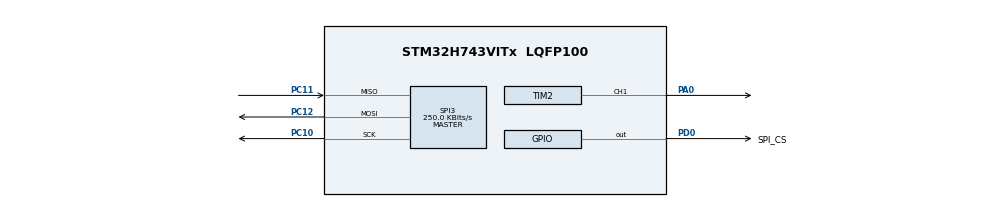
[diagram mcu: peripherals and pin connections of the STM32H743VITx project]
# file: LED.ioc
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Dma.Request0=SPI3_RX
Dma.SPI3_RX.0.Direction=DMA_PERIPH_TO_MEMORY
Dma.SPI3_RX.0.EventEnable=DISABLE
Dma.SPI3_RX.0.FIFOMode=DMA_FIFOMODE_DISABLE
Dma.SPI3_RX.0.Instance=DMA1_Stream3
Dma.SPI3_RX.0.MemDataAlignment=DMA_MDATAALIGN_BYTE
Dma.SPI3_RX.0.MemInc=DMA_MINC_ENABLE
Dma.SPI3_RX.0.Mode=DMA_CIRCULAR
Dma.SPI3_RX.0.PeriphDataAlignment=DMA_PDATAALIGN_BYTE
Dma.SPI3_RX.0.PeriphInc=DMA_PINC_DISABLE
Dma.SPI3_RX.0.Polarity=HAL_DMAMUX_REQ_GEN_RISING
Dma.SPI3_RX.0.Priority=DMA_PRIORITY_LOW
Dma.SPI3_RX.0.RequestNumber=1
Dma.SPI3_RX.0.SignalID=NONE
Dma.SPI3_RX.0.SyncEnable=DISABLE
Dma.SPI3_RX.0.SyncPolarity=HAL_DMAMUX_SYNC_NO_EVENT
Dma.SPI3_RX.0.SyncRequestNumber=1
Dma.SPI3_RX.0.SyncSignalID=NONE
Mcu.Family=STM32H7
Mcu.Name=STM32H743VITx
Mcu.Package=LQFP100
NVIC.DMA1_Stream3_IRQn=true\:0\:0\:false\:false\:true\:false\:true
NVIC.PriorityGroup=NVIC_PRIORITYGROUP_4
NVIC.SPI3_IRQn=true\:0\:0\:false\:false\:true\:false\:true
PA0.Signal=S_TIM2_CH1
PA13\ (JTMS/SWDIO).Mode=JTAG_4_pins
PA13\ (JTMS/SWDIO).Signal=DEBUG_JTMS-SWDIO
PA14\ (JTCK/SWCLK).Mode=JTAG_4_pins
PA14\ (JTCK/SWCLK).Signal=DEBUG_JTCK-SWCLK
PA15\ (JTDI).Mode=JTAG_4_pins
PA15\ (JTDI).Signal=DEBUG_JTDI
PB3\ (JTDO/TRACESWO).Mode=JTAG_4_pins
PB3\ (JTDO/TRACESWO).Signal=DEBUG_JTDO-SWO
PC10.Mode=Full_Duplex_Master
PC10.Signal=SPI3_SCK
PC11.Mode=Full_Duplex_Master
PC11.Signal=SPI3_MISO
PC12.Mode=Full_Duplex_Master
PC12.Signal=SPI3_MOSI
PD0.GPIO_Label=SPI_CS
PD0.Signal=GPIO_Output
PH0-OSC_IN\ (PH0).Mode=HSE-External-Oscillator
PH0-OSC_IN\ (PH0).Signal=RCC_OSC_IN
PH1-OSC_OUT\ (PH1).Mode=HSE-External-Oscillator
PH1-OSC_OUT\ (PH1).Signal=RCC_OSC_OUT
ProjectManager.HeapSize=0x200
ProjectManager.StackSize=0x400
ProjectManager.TargetToolchain=MDK-ARM V5
RCC.ADCFreq_Value=16125000
RCC.APB1Freq_Value=100000000
RCC.APB2Freq_Value=100000000
RCC.APB3Freq_Value=100000000
RCC.APB4Freq_Value=100000000
RCC.CortexFreq_Value=400000000
RCC.D1PPRE=RCC_APB3_DIV2
RCC.D2PPRE1=RCC_APB1_DIV2
RCC.D2PPRE2=RCC_APB2_DIV2
RCC.D3PPRE=RCC_APB4_DIV2
RCC.DIVM1=1
RCC.DIVN1=100
RCC.EnbaleCSS=true
RCC.HCLKFreq_Value=200000000
RCC.HPRE=RCC_HCLK_DIV2
RCC.HSE_VALUE=8000000
RCC.PLL2FRACN=0
RCC.PLL2_VCI_Range-AdvancedSettings=RCC_PLL2VCIRANGE_0
RCC.PLL3FRACN=0
RCC.PLLFRACN=0
RCC.PLLSourceVirtual=RCC_PLLSOURCE_HSE
RCC.SPI123CLockSelection=RCC_SPI123CLKSOURCE_CLKP
RCC.SYSCLKFreq_VALUE=400000000
RCC.SYSCLKSource=RCC_SYSCLKSOURCE_PLLCLK
RCC.USBFreq_Value=400000000
SH.S_TIM2_CH1.0=TIM2_CH1,PWM Generation1 CH1
SPI3.BaudRatePrescaler=SPI_BAUDRATEPRESCALER_256
SPI3.CLKPhase=SPI_PHASE_2EDGE
SPI3.CLKPolarity=SPI_POLARITY_HIGH
SPI3.CalculateBaudRate=250.0 KBits/s
SPI3.DataSize=SPI_DATASIZE_8BIT
SPI3.Direction=SPI_DIRECTION_2LINES
SPI3.Mode=SPI_MODE_MASTER
SPI3.VirtualType=VM_MASTER
TIM2.Channel-PWM\ Generation1\ CH1=TIM_CHANNEL_1
TIM2.Period=1000
TIM2.Prescaler=240-1
TIM2.Pulse-PWM\ Generation1\ CH1=500
VP_TIM2_VS_ClockSourceINT.Mode=Internal
board=custom

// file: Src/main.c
/* USER CODE BEGIN Header */
/**
  ******************************************************************************
  * @file           : main.c
  * @brief          : Main program body
  ******************************************************************************
  * @attention
  *
  * <h2><center>&copy; Copyright (c) 2019 STMicroelectronics.
  * All rights reserved.</center></h2>
  *
  * This software component is licensed by ST under BSD 3-Clause license,
  * the "License"; You may not use this file except in compliance with the
  * License. You may obtain a copy of the License at:
  *                        opensource.org/licenses/BSD-3-Clause
  *
  ******************************************************************************
  */
/* USER CODE END Header */

#include "main.h"
#include "dma.h"
#include "spi.h"
#include "tim.h"
#include "gpio.h"

/* USER CODE BEGIN Includes */
#include "AD779x.h"
/* USER CODE END Includes */

void SystemClock_Config(void);
/* USER CODE BEGIN PFP */
float voltage;
/* USER CODE END PFP */

int main(void)
{

  /* MCU Configuration--------------------------------------------------------*/

  /* Reset of all peripherals, Initializes the Flash interface and the Systick. */
  HAL_Init();

  /* Configure the system clock */
  SystemClock_Config();

  /* Initialize all configured peripherals */
  MX_GPIO_Init();
  MX_DMA_Init();
  MX_TIM2_Init();
  MX_SPI3_Init();
  /* USER CODE BEGIN 2 */
	HAL_Delay(10);

   AD779X_Init();		// ��ҪУ׼
	int data = 0;

  /* USER CODE END 2 */

  /* Infinite loop */
    while(1)
    {

    /* USER CODE BEGIN 3 */
//		int state = AD779X_GetStatus();
//		if(state>>7 == 0)
//		{
//			data = AD779X_ReadDataRegister24();
//		    voltage = (float)data/(0xffffff )*2.494;
//		}
		if(AD779X_CheckReadySW()==AD779X_SR_RDY)
		{
			data = AD779X_ReadDataRegister24();
		    voltage = (float)data/(0xffffff )*2.494;
		}
		//		AD779X_HWDetect();
//		HAL_Delay(1);
    }
  /* USER CODE END 3 */
}

void SystemClock_Config(void)
{
  RCC_OscInitTypeDef RCC_OscInitStruct = {0};
  RCC_ClkInitTypeDef RCC_ClkInitStruct = {0};
  RCC_PeriphCLKInitTypeDef PeriphClkInitStruct = {0};

  /** Supply configuration update enable
  */
  HAL_PWREx_ConfigSupply(PWR_LDO_SUPPLY);
  /** Configure the main internal regulator output voltage
  */
  __HAL_PWR_VOLTAGESCALING_CONFIG(PWR_REGULATOR_VOLTAGE_SCALE1);

  while(!__HAL_PWR_GET_FLAG(PWR_FLAG_VOSRDY)) {}
  /** Initializes the CPU, AHB and APB busses clocks
  */
  RCC_OscInitStruct.OscillatorType = RCC_OSCILLATORTYPE_HSI|RCC_OSCILLATORTYPE_HSE;
  RCC_OscInitStruct.HSEState = RCC_HSE_ON;
  RCC_OscInitStruct.HSIState = RCC_HSI_DIV1;
  RCC_OscInitStruct.HSICalibrationValue = RCC_HSICALIBRATION_DEFAULT;
  RCC_OscInitStruct.PLL.PLLState = RCC_PLL_ON;
  RCC_OscInitStruct.PLL.PLLSource = RCC_PLLSOURCE_HSE;
  RCC_OscInitStruct.PLL.PLLM = 1;
  RCC_OscInitStruct.PLL.PLLN = 100;
  RCC_OscInitStruct.PLL.PLLP = 2;
  RCC_OscInitStruct.PLL.PLLQ = 2;
  RCC_OscInitStruct.PLL.PLLR = 2;
  RCC_OscInitStruct.PLL.PLLRGE = RCC_PLL1VCIRANGE_3;
  RCC_OscInitStruct.PLL.PLLVCOSEL = RCC_PLL1VCOWIDE;
  RCC_OscInitStruct.PLL.PLLFRACN = 0;
  if (HAL_RCC_OscConfig(&RCC_OscInitStruct) != HAL_OK)
  {
    Error_Handler();
  }
  /** Initializes the CPU, AHB and APB busses clocks
  */
  RCC_ClkInitStruct.ClockType = RCC_CLOCKTYPE_HCLK|RCC_CLOCKTYPE_SYSCLK
                              |RCC_CLOCKTYPE_PCLK1|RCC_CLOCKTYPE_PCLK2
                              |RCC_CLOCKTYPE_D3PCLK1|RCC_CLOCKTYPE_D1PCLK1;
  RCC_ClkInitStruct.SYSCLKSource = RCC_SYSCLKSOURCE_PLLCLK;
  RCC_ClkInitStruct.SYSCLKDivider = RCC_SYSCLK_DIV1;
  RCC_ClkInitStruct.AHBCLKDivider = RCC_HCLK_DIV2;
  RCC_ClkInitStruct.APB3CLKDivider = RCC_APB3_DIV2;
  RCC_ClkInitStruct.APB1CLKDivider = RCC_APB1_DIV2;
  RCC_ClkInitStruct.APB2CLKDivider = RCC_APB2_DIV2;
  RCC_ClkInitStruct.APB4CLKDivider = RCC_APB4_DIV2;

  if (HAL_RCC_ClockConfig(&RCC_ClkInitStruct, FLASH_LATENCY_2) != HAL_OK)
  {
    Error_Handler();
  }
  PeriphClkInitStruct.PeriphClockSelection = RCC_PERIPHCLK_SPI3|RCC_PERIPHCLK_CKPER;
  PeriphClkInitStruct.CkperClockSelection = RCC_CLKPSOURCE_HSI;
  PeriphClkInitStruct.Spi123ClockSelection = RCC_SPI123CLKSOURCE_CLKP;
  if (HAL_RCCEx_PeriphCLKConfig(&PeriphClkInitStruct) != HAL_OK)
  {
    Error_Handler();
  }
  /** Enables the Clock Security System
  */
  HAL_RCC_EnableCSS();
}

void Error_Handler(void)
{
}

/************************ (C) COPYRIGHT STMicroelectronics *****END OF FILE****/
